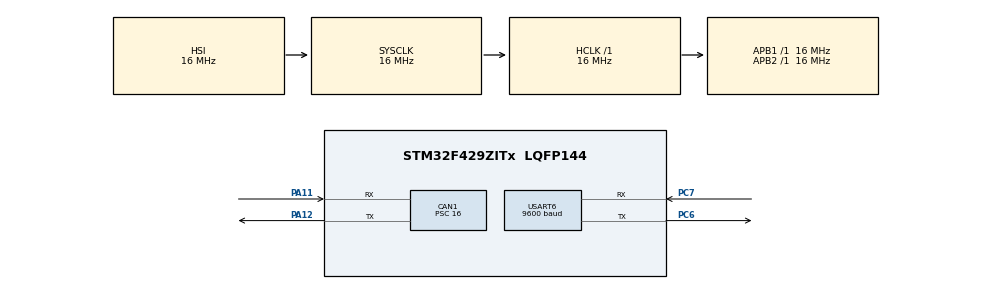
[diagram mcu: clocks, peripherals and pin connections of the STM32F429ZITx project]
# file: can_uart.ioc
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CAN1.BS1=CAN_BS1_8TQ
CAN1.CalculateBaudRate=100000
CAN1.CalculateTimeBit=10000
CAN1.CalculateTimeQuantum=1000.0
CAN1.Prescaler=16
Mcu.Family=STM32F4
Mcu.Name=STM32F429ZITx
Mcu.Package=LQFP144
NVIC.CAN1_RX0_IRQn=true\:0\:0\:false\:false\:true\:true\:true\:true
NVIC.CAN1_RX1_IRQn=true\:0\:0\:false\:false\:true\:true\:true\:true
NVIC.CAN1_SCE_IRQn=true\:0\:0\:false\:false\:true\:true\:true\:true
NVIC.CAN1_TX_IRQn=true\:0\:0\:false\:false\:true\:true\:true\:true
NVIC.PriorityGroup=NVIC_PRIORITYGROUP_4
PA11.Mode=CAN_Activate
PA11.Signal=CAN1_RX
PA12.Mode=CAN_Activate
PA12.Signal=CAN1_TX
PC6.Mode=Asynchronous
PC6.Signal=USART6_TX
PC7.Mode=Asynchronous
PC7.Signal=USART6_RX
PH0/OSC_IN.Mode=HSE-External-Oscillator
PH0/OSC_IN.Signal=RCC_OSC_IN
PH1/OSC_OUT.Mode=HSE-External-Oscillator
PH1/OSC_OUT.Signal=RCC_OSC_OUT
ProjectManager.HeapSize=0x200
ProjectManager.StackSize=0x400
ProjectManager.TargetToolchain=STM32CubeIDE
RCC.AHBFreq_Value=16000000
RCC.APB1Freq_Value=16000000
RCC.APB2Freq_Value=16000000
RCC.CortexFreq_Value=16000000
RCC.HSE_VALUE=25000000
RCC.HSI_VALUE=16000000
RCC.LSE_VALUE=32768
RCC.SYSCLKFreq_VALUE=16000000
RCC.VCOOutputFreq_Value=192000000
USART6.BaudRate=9600
USART6.VirtualMode=VM_ASYNC
board=custom

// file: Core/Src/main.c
/* USER CODE BEGIN Header */
/**
  ******************************************************************************
  * @file           : main.c
  * @brief          : Main program body
  ******************************************************************************
  * @attention
  *
  * Copyright (c) 2024 STMicroelectronics.
  * All rights reserved.
  *
  * This software is licensed under terms that can be found in the LICENSE file
  * in the root directory of this software component.
  * If no LICENSE file comes with this software, it is provided AS-IS.
  *
  ******************************************************************************
  */
/* USER CODE END Header */
#include "main.h"
#include <stdio.h>

CAN_HandleTypeDef hcan1;

UART_HandleTypeDef huart6;

/* USER CODE BEGIN PV */
CAN_RxHeaderTypeDef RxHeader;
uint8_t RxData[32];
/* USER CODE END PV */

void SystemClock_Config(void);
static void MX_GPIO_Init(void);
static void MX_CAN1_Init(void);
static void MX_USART6_UART_Init(void);

int main(void)
{

  /* MCU Configuration--------------------------------------------------------*/

  /* Reset of all peripherals, Initializes the Flash interface and the Systick. */
  HAL_Init();

  /* Configure the system clock */
  SystemClock_Config();

  /* Initialize all configured peripherals */
  MX_GPIO_Init();
  MX_CAN1_Init();
  MX_USART6_UART_Init();
  /* USER CODE BEGIN 2 */
  HAL_CAN_Start(&hcan1);
  HAL_CAN_ActivateNotification(&hcan1, CAN_IT_RX_FIFO0_MSG_PENDING);
  /* USER CODE END 2 */

  /* Infinite loop */
  while (1)
  {

  }
}

void SystemClock_Config(void)
{
  RCC_OscInitTypeDef RCC_OscInitStruct = {0};
  RCC_ClkInitTypeDef RCC_ClkInitStruct = {0};

  /** Configure the main internal regulator output voltage
  */
  __HAL_RCC_PWR_CLK_ENABLE();
  __HAL_PWR_VOLTAGESCALING_CONFIG(PWR_REGULATOR_VOLTAGE_SCALE3);

  /** Initializes the RCC Oscillators according to the specified parameters
  * in the RCC_OscInitTypeDef structure.
  */
  RCC_OscInitStruct.OscillatorType = RCC_OSCILLATORTYPE_HSI;
  RCC_OscInitStruct.HSIState = RCC_HSI_ON;
  RCC_OscInitStruct.HSICalibrationValue = RCC_HSICALIBRATION_DEFAULT;
  RCC_OscInitStruct.PLL.PLLState = RCC_PLL_NONE;
  if (HAL_RCC_OscConfig(&RCC_OscInitStruct) != HAL_OK)
  {
    Error_Handler();
  }

  /** Initializes the CPU, AHB and APB buses clocks
  */
  RCC_ClkInitStruct.ClockType = RCC_CLOCKTYPE_HCLK|RCC_CLOCKTYPE_SYSCLK
                              |RCC_CLOCKTYPE_PCLK1|RCC_CLOCKTYPE_PCLK2;
  RCC_ClkInitStruct.SYSCLKSource = RCC_SYSCLKSOURCE_HSI;
  RCC_ClkInitStruct.AHBCLKDivider = RCC_SYSCLK_DIV1;
  RCC_ClkInitStruct.APB1CLKDivider = RCC_HCLK_DIV1;
  RCC_ClkInitStruct.APB2CLKDivider = RCC_HCLK_DIV1;

  if (HAL_RCC_ClockConfig(&RCC_ClkInitStruct, FLASH_LATENCY_0) != HAL_OK)
  {
    Error_Handler();
  }
}

static void MX_CAN1_Init(void)
{

  hcan1.Instance = CAN1;
  hcan1.Init.Prescaler = 555;
  hcan1.Init.Mode = CAN_MODE_NORMAL;
  hcan1.Init.SyncJumpWidth = CAN_SJW_1TQ;
  hcan1.Init.TimeSeg1 = CAN_BS1_1TQ;
  hcan1.Init.TimeSeg2 = CAN_BS2_1TQ;
  hcan1.Init.TimeTriggeredMode = DISABLE;
  hcan1.Init.AutoBusOff = DISABLE;
  hcan1.Init.AutoWakeUp = DISABLE;
  hcan1.Init.AutoRetransmission = DISABLE;
  hcan1.Init.ReceiveFifoLocked = DISABLE;
  hcan1.Init.TransmitFifoPriority = DISABLE;
  if (HAL_CAN_Init(&hcan1) != HAL_OK)
  {
    Error_Handler();
  }

}

static void MX_USART6_UART_Init(void)
{

  huart6.Instance = USART6;
  huart6.Init.BaudRate = 9600;
  huart6.Init.WordLength = UART_WORDLENGTH_8B;
  huart6.Init.StopBits = UART_STOPBITS_1;
  huart6.Init.Parity = UART_PARITY_NONE;
  huart6.Init.Mode = UART_MODE_TX_RX;
  huart6.Init.HwFlowCtl = UART_HWCONTROL_NONE;
  huart6.Init.OverSampling = UART_OVERSAMPLING_16;
  if (HAL_UART_Init(&huart6) != HAL_OK)
  {
    Error_Handler();
  }

}

static void MX_GPIO_Init(void)
{

  /* GPIO Ports Clock Enable */
  __HAL_RCC_GPIOC_CLK_ENABLE();
  __HAL_RCC_GPIOA_CLK_ENABLE();

}

/* USER CODE BEGIN 4 */
void UART_SendMessage(uint32_t can_id, uint8_t* data, uint8_t dlc)
{
    char buffer[128];
    int len = snprintf(buffer, sizeof(buffer), "ID:%d DLC:%d Data:", can_id, dlc);

    for (int i = 0; i < dlc; i++)
    {
        len += snprintf(buffer + len, sizeof(buffer) - len, " %d", data[i]);
    }
    strcat(buffer, "\r\n");

    HAL_UART_Transmit(&huart6, (uint8_t*)buffer, strlen(buffer), HAL_MAX_DELAY);
}
/* USER CODE END 4 */

void Error_Handler(void)
{
  __disable_irq();
  while (1)
  {
  }
}
